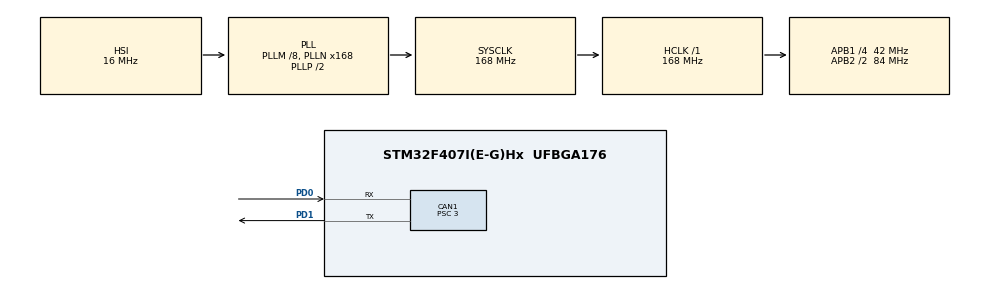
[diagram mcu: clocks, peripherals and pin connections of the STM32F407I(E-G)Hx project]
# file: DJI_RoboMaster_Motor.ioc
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CAN1.ABOM=ENABLE
CAN1.BS1=CAN_BS1_10TQ
CAN1.BS2=CAN_BS2_3TQ
CAN1.CalculateBaudRate=1000000
CAN1.CalculateTimeBit=1000
CAN1.CalculateTimeQuantum=71.42857142857143
CAN1.NART=ENABLE
CAN1.Prescaler=3
Mcu.Family=STM32F4
Mcu.Name=STM32F407I(E-G)Hx
Mcu.Package=UFBGA176
NVIC.CAN1_RX0_IRQn=true\:0\:0\:true\:false\:true\:true\:true\:true
NVIC.CAN1_RX1_IRQn=true\:0\:0\:true\:false\:true\:true\:true\:true
NVIC.PriorityGroup=NVIC_PRIORITYGROUP_4
NVIC.TIM8_UP_TIM13_IRQn=true\:3\:0\:true\:false\:true\:true\:true\:true
PA13.Mode=Serial_Wire
PA13.Signal=SYS_JTMS-SWDIO
PA14.Mode=Serial_Wire
PA14.Signal=SYS_JTCK-SWCLK
PD0.Mode=CAN_Activate
PD0.Signal=CAN1_RX
PD1.Mode=CAN_Activate
PD1.Signal=CAN1_TX
PH0-OSC_IN.Mode=HSE-External-Oscillator
PH0-OSC_IN.Signal=RCC_OSC_IN
PH1-OSC_OUT.Mode=HSE-External-Oscillator
PH1-OSC_OUT.Signal=RCC_OSC_OUT
ProjectManager.HeapSize=0x200
ProjectManager.StackSize=0x400
ProjectManager.TargetToolchain=CMake
RCC.48MHZClocksFreq_Value=84000000
RCC.AHBFreq_Value=168000000
RCC.APB1CLKDivider=RCC_HCLK_DIV4
RCC.APB1Freq_Value=42000000
RCC.APB1TimFreq_Value=84000000
RCC.APB2CLKDivider=RCC_HCLK_DIV2
RCC.APB2Freq_Value=84000000
RCC.APB2TimFreq_Value=168000000
RCC.CortexFreq_Value=168000000
RCC.HCLKFreq_Value=168000000
RCC.HSE_VALUE=12000000
RCC.HSI_VALUE=16000000
RCC.LSE_VALUE=32768
RCC.PLLM=8
RCC.PLLN=168
RCC.SYSCLKFreq_VALUE=168000000
RCC.SYSCLKSource=RCC_SYSCLKSOURCE_PLLCLK
RCC.VCOOutputFreq_Value=336000000
TIM8.AutoReloadPreload=TIM_AUTORELOAD_PRELOAD_ENABLE
TIM8.Period=1000-1
TIM8.Prescaler=168-1
VP_TIM8_VS_ClockSourceINT.Mode=Internal
board=custom

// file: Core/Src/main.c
/* USER CODE BEGIN Header */
/**
  ******************************************************************************
  * @file           : main.c
  * @brief          : Main program body
  ******************************************************************************
  * @attention
  *
  * Copyright (c) 2026 STMicroelectronics.
  * All rights reserved.
  *
  * This software is licensed under terms that can be found in the LICENSE file
  * in the root directory of this software component.
  * If no LICENSE file comes with this software, it is provided AS-IS.
  *
  ******************************************************************************
  */
/* USER CODE END Header */
#include "main.h"
#include "can.h"
#include "tim.h"
#include "gpio.h"

/* USER CODE BEGIN Includes */
#include "drv_can.h"
#include "dvc_DJI_M3508.h"

/* USER CODE END Includes */

/* USER CODE BEGIN PV */
Struct_RM_Motor_M3508 LF_M3508;
Struct_RM_Motor_M3508 LB_M3508;
Struct_RM_Motor_M3508 RB_M3508;
Struct_RM_Motor_M3508 RF_M3508;

float LF_Torque = 0.0f;
float LB_Torque = 0.0f;
float RB_Torque = 0.0f;
float RF_Torque = 0.0f;
/* USER CODE END PV */

void SystemClock_Config(void);
/* USER CODE BEGIN PFP */
void DJI_RM_CAN_Callback(Struct_CAN_Rx_Buffer *Rx_Buffer);
/* USER CODE END PFP */

/* USER CODE BEGIN 0 */
void DJI_RM_CAN_Callback(Struct_CAN_Rx_Buffer *Rx_Buffer)
{
  switch (Rx_Buffer->Header.StdId)
  {
    case (0x201):
      {
        DJI_M3508_CAN_RxCpltCallback(&LF_M3508, Rx_Buffer->Data);
        LF_Torque = DJI_M3508_Get_Now_Torque(&LF_M3508);
      }
    break;
    case (0x202):
      {
        DJI_M3508_CAN_RxCpltCallback(&LB_M3508, Rx_Buffer->Data);
        LB_Torque = DJI_M3508_Get_Now_Torque(&LB_M3508);
      }
    break;
    case (0x203):
      {
        DJI_M3508_CAN_RxCpltCallback(&RB_M3508, Rx_Buffer->Data);
        RB_Torque = DJI_M3508_Get_Now_Torque(&RB_M3508);
      }
    break;
    case (0x204):
      {
        DJI_M3508_CAN_RxCpltCallback(&RF_M3508, Rx_Buffer->Data);
        RF_Torque = DJI_M3508_Get_Now_Torque(&RF_M3508);
      }
    break;
    default:
    break;
  }
}

void HAL_TIM_PeriodElapsedCallback(TIM_HandleTypeDef *htim)
{
  if (htim->Instance == TIM8)
  {
    DJI_M3508_TIM_Alive_PeriodElapsedCallback(&LF_M3508);
    DJI_M3508_TIM_Alive_PeriodElapsedCallback(&LB_M3508);
    DJI_M3508_TIM_Alive_PeriodElapsedCallback(&RB_M3508);
    DJI_M3508_TIM_Alive_PeriodElapsedCallback(&RF_M3508);

    DJI_M3508_TIM_PID_PeriodElapsedCallback(&LF_M3508);
    DJI_M3508_TIM_PID_PeriodElapsedCallback(&LB_M3508);
    DJI_M3508_TIM_PID_PeriodElapsedCallback(&RB_M3508);
    DJI_M3508_TIM_PID_PeriodElapsedCallback(&RF_M3508);

    TIM_CAN_PeriodElapsedCallback();
  }
}
/* USER CODE END 0 */

int main(void)
{

  /* MCU Configuration--------------------------------------------------------*/

  /* Reset of all peripherals, Initializes the Flash interface and the Systick. */
  HAL_Init();

  /* Configure the system clock */
  SystemClock_Config();

  /* Initialize all configured peripherals */
  MX_GPIO_Init();
  MX_CAN1_Init();
  MX_TIM8_Init();
  /* USER CODE BEGIN 2 */
  HAL_TIM_Base_Start_IT(&htim8);
  CAN_Init(&hcan1, DJI_RM_CAN_Callback);
  DJI_M3508_Init(&hcan1, &LF_M3508, RM_Motor_ID_0x201, Control_Method_OMEGA, 3591.0f/187.0f, 2.5f);
  DJI_M3508_Init(&hcan1, &LB_M3508, RM_Motor_ID_0x202, Control_Method_OMEGA, 3591.0f/187.0f, 2.5f);
  DJI_M3508_Init(&hcan1, &RB_M3508, RM_Motor_ID_0x203, Control_Method_OMEGA, 3591.0f/187.0f, 2.5f);
  DJI_M3508_Init(&hcan1, &RF_M3508, RM_Motor_ID_0x204, Control_Method_OMEGA, 3591.0f/187.0f, 2.5f);
  PID_Init(&LF_M3508.PID_Omega, 500.0f, 0.0f, 0.0f, 0.0f, 0.0f, 16384.0f,
           0.001f, 0.0f,0.0f, 0.0f, 0.0f, 1);
  PID_Init(&LB_M3508.PID_Omega, 500.0f, 0.0f, 0.0f, 0.0f, 0.0f, 16384.0f,
           0.001f, 0.0f, 0.0f, 0.0f, 0.0f, 1);
  PID_Init(&RB_M3508.PID_Omega, 100.0f, 0.7f, 0.0f, 0.0f, 0.0f, 16384.0f,
           0.001f, 0.0f, 0.0f, 0.0f, 0.0f, 1);
  PID_Init(&RF_M3508.PID_Omega, 500.0f, 0.0f, 0.0f, 0.0f, 0.0f, 16384.0f,
           0.001f, 0.0f, 0.0f, 0.0f, 0.0f, 1);
  /* USER CODE END 2 */

  /* Infinite loop */
  /* USER CODE BEGIN WHILE */
  while (1)
  {
    DJI_M3508_Set_Target_Omega(&LF_M3508, 10.0f);
    DJI_M3508_Set_Target_Omega(&LB_M3508, 10.0f);
    DJI_M3508_Set_Target_Omega(&RB_M3508, 10.0f);
    DJI_M3508_Set_Target_Omega(&RF_M3508, 10.0f);
    HAL_Delay(5000);

    DJI_M3508_Set_Target_Omega(&LF_M3508, 30.0f);
    DJI_M3508_Set_Target_Omega(&LB_M3508, 30.0f);
    DJI_M3508_Set_Target_Omega(&RB_M3508, 30.0f);
    DJI_M3508_Set_Target_Omega(&RF_M3508, 30.0f);
    HAL_Delay(5000);

    /* USER CODE END WHILE */

  }
}

void SystemClock_Config(void)
{
  RCC_OscInitTypeDef RCC_OscInitStruct = {0};
  RCC_ClkInitTypeDef RCC_ClkInitStruct = {0};

  /** Configure the main internal regulator output voltage
  */
  __HAL_RCC_PWR_CLK_ENABLE();
  __HAL_PWR_VOLTAGESCALING_CONFIG(PWR_REGULATOR_VOLTAGE_SCALE1);

  /** Initializes the RCC Oscillators according to the specified parameters
  * in the RCC_OscInitTypeDef structure.
  */
  RCC_OscInitStruct.OscillatorType = RCC_OSCILLATORTYPE_HSI;
  RCC_OscInitStruct.HSIState = RCC_HSI_ON;
  RCC_OscInitStruct.HSICalibrationValue = RCC_HSICALIBRATION_DEFAULT;
  RCC_OscInitStruct.PLL.PLLState = RCC_PLL_ON;
  RCC_OscInitStruct.PLL.PLLSource = RCC_PLLSOURCE_HSI;
  RCC_OscInitStruct.PLL.PLLM = 8;
  RCC_OscInitStruct.PLL.PLLN = 168;
  RCC_OscInitStruct.PLL.PLLP = RCC_PLLP_DIV2;
  RCC_OscInitStruct.PLL.PLLQ = 4;
  if (HAL_RCC_OscConfig(&RCC_OscInitStruct) != HAL_OK)
  {
    Error_Handler();
  }

  /** Initializes the CPU, AHB and APB buses clocks
  */
  RCC_ClkInitStruct.ClockType = RCC_CLOCKTYPE_HCLK|RCC_CLOCKTYPE_SYSCLK
                              |RCC_CLOCKTYPE_PCLK1|RCC_CLOCKTYPE_PCLK2;
  RCC_ClkInitStruct.SYSCLKSource = RCC_SYSCLKSOURCE_PLLCLK;
  RCC_ClkInitStruct.AHBCLKDivider = RCC_SYSCLK_DIV1;
  RCC_ClkInitStruct.APB1CLKDivider = RCC_HCLK_DIV4;
  RCC_ClkInitStruct.APB2CLKDivider = RCC_HCLK_DIV2;

  if (HAL_RCC_ClockConfig(&RCC_ClkInitStruct, FLASH_LATENCY_5) != HAL_OK)
  {
    Error_Handler();
  }
}

void Error_Handler(void)
{
  __disable_irq();
  while (1)
  {
  }
}
